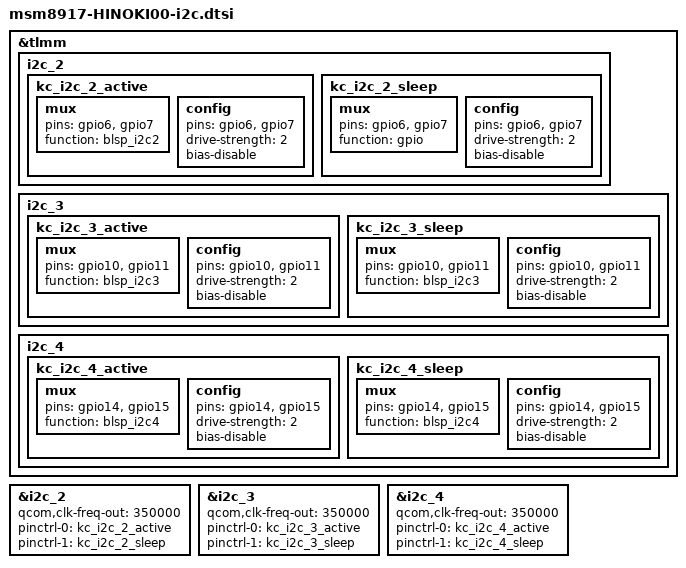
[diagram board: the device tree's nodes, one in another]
/*
 * This software is contributed or developed by KYOCERA Corporation.
 * (C) 2019 KYOCERA Corporation
 *
 * This program is free software; you can redistribute it and/or modify
 * it under the terms of the GNU General Public License version 2 and
 * only version 2 as published by the Free Software Foundation.
 *
 * This program is distributed in the hope that it will be useful,
 * but WITHOUT ANY WARRANTY; without even the implied warranty of
 * MERCHANTABILITY or FITNESS FOR A PARTICULAR PURPOSE.  See the
 * GNU General Public License for more details.
 */

&tlmm {
    /delete-node/ i2c_2;
    i2c_2 {
        kc_i2c_2_active: kc_i2c_2_active {
            /* active state */
            mux {
                pins = "gpio6", "gpio7";
                function = "blsp_i2c2";
            };

            config {
                pins = "gpio6", "gpio7";
                drive-strength = <2>;
                bias-disable;
            };
        };

        kc_i2c_2_sleep: kc_i2c_2_sleep {
            /* suspended state */
            mux {
                pins = "gpio6", "gpio7";
                function = "gpio";
            };

            config {
                pins = "gpio6", "gpio7";
                drive-strength = <2>;
                bias-disable;
            };
        };
    };

    /delete-node/ i2c_3;
    i2c_3 {
        kc_i2c_3_active: kc_i2c_3_active {
            /* active state */
            mux {
                pins = "gpio10", "gpio11";
                function = "blsp_i2c3";
            };

            config {
                pins = "gpio10", "gpio11";
                drive-strength = <2>;
                bias-disable;
            };
        };

        kc_i2c_3_sleep: kc_i2c_3_sleep {
            /* suspended state */
            mux {
                pins = "gpio10", "gpio11";
                function = "blsp_i2c3";
            };

            config {
                pins = "gpio10", "gpio11";
                drive-strength = <2>;
                bias-disable;
            };
        };
    };

    /delete-node/ i2c_4;
    i2c_4 {
        kc_i2c_4_active: kc_i2c_4_active {
            /* active state */
            mux {
                pins = "gpio14", "gpio15";
                function = "blsp_i2c4";
            };

            config {
                pins = "gpio14", "gpio15";
                drive-strength = <2>;
                bias-disable;
            };
        };

        kc_i2c_4_sleep: kc_i2c_4_sleep {
            /* suspended state */
            mux {
                pins = "gpio14", "gpio15";
                function = "blsp_i2c4";
            };

            config {
                pins = "gpio14", "gpio15";
                drive-strength = <2>;
                bias-disable;
            };
        };
    };
};

&i2c_2 {
    qcom,clk-freq-out = <350000>;
    /delete-property/ pinctrl-0;
    /delete-property/ pinctrl-1;
    pinctrl-0 = <&kc_i2c_2_active>;
    pinctrl-1 = <&kc_i2c_2_sleep>;
    status = "ok";
};

&i2c_3 {
    qcom,clk-freq-out = <350000>;
    /delete-property/ pinctrl-0;
    /delete-property/ pinctrl-1;
    pinctrl-0 = <&kc_i2c_3_active>;
    pinctrl-1 = <&kc_i2c_3_sleep>;
    status = "ok";
};

&i2c_4 {
    qcom,clk-freq-out = <350000>;
    /delete-property/ pinctrl-0;
    /delete-property/ pinctrl-1;
    pinctrl-0 = <&kc_i2c_4_active>;
    pinctrl-1 = <&kc_i2c_4_sleep>;
    status = "ok";
};

